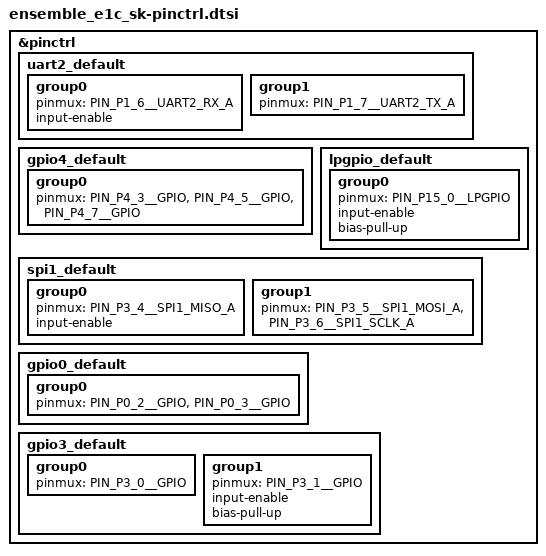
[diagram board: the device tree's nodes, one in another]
/*
 * SPDX-FileCopyrightText: Copyright Alif Semiconductor
 * SPDX-License-Identifier: Apache-2.0
 */

#include <zephyr/dt-bindings/pinctrl/alif-ensemble-e1c-pinctrl.h>

&pinctrl {
	uart2_default: uart2_default {
		group0 {
			pinmux = <PIN_P1_6__UART2_RX_A>;
			input-enable;
		};

		group1 {
			pinmux = <PIN_P1_7__UART2_TX_A>;
		};
	};

	gpio4_default: gpio4_default {
		group0 {
			/* Multicolor LED0: blue on P4_3, green on P4_5, red on P4_7 */
			pinmux = <PIN_P4_3__GPIO>,
				 <PIN_P4_5__GPIO>,
				 <PIN_P4_7__GPIO>;
		};
	};

	lpgpio_default: lpgpio_default {
		group0 {
			/* User switch SW2, no external pull-up */
			pinmux = <PIN_P15_0__LPGPIO>;
			input-enable;
			bias-pull-up;
		};
	};

	spi1_default: spi1_default {
		group0 {
			pinmux = <PIN_P3_4__SPI1_MISO_A>;
			input-enable;
		};

		group1 {
			pinmux = <PIN_P3_5__SPI1_MOSI_A>,
				 <PIN_P3_6__SPI1_SCLK_A>;
		};
	};

	gpio0_default: gpio0_default {
		group0 {
			/* mikroBUS AN on P0_2, CS on P0_3 */
			pinmux = <PIN_P0_2__GPIO>,
				 <PIN_P0_3__GPIO>;
		};
	};

	gpio3_default: gpio3_default {
		group0 {
			/* mikroBUS RST on P3_0 */
			pinmux = <PIN_P3_0__GPIO>;
		};

		group1 {
			/* mikroBUS INT on P3_1 */
			pinmux = <PIN_P3_1__GPIO>;
			input-enable;
			bias-pull-up;
		};
	};
};
